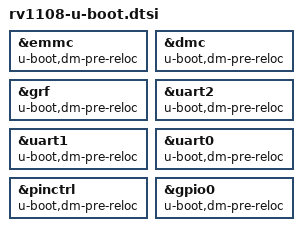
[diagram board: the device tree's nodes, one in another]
/*
 * (C) Copyright 2019 Rockchip Electronics Co., Ltd
 *
 * SPDX-License-Identifier:     GPL-2.0+
 */

&emmc {
	u-boot,dm-pre-reloc;
};

&dmc {
	u-boot,dm-pre-reloc;
};

&grf {
	u-boot,dm-pre-reloc;
};

&uart2 {
	u-boot,dm-pre-reloc;
};
&uart1 {
	u-boot,dm-pre-reloc;
};
&uart0 {
	u-boot,dm-pre-reloc;
};

&pinctrl {
	u-boot,dm-pre-reloc;
};

&gpio0 {
	u-boot,dm-pre-reloc;
};
